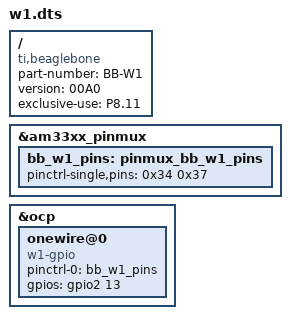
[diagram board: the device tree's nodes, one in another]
/*
* Copyright (C) 2012 Texas Instruments Incorporated - http://www.ti.com/
*
* This program is free software; you can redistribute it and/or modify
* it under the terms of the GNU General Public License version 2 as
* published by the Free Software Foundation.
* 
* Modified  by Russell Senior from the weather cape's DTS file.
* Minor formatting by C W Rose.
* 
* 
* Configuring One-wire protocol for Beaglebone Black, following instructions at
* http://www.bonebrews.com/temperature-monitoring-with-the-ds18b20-on-a-beaglebone-black/
*
* This code configures pin P8.11; if using a different pin, change the following:
* - exclusive-use
* - first entry in pinctrl-single,pins
*/



/dts-v1/;
/plugin/;

/ {
    compatible = "ti,beaglebone", "ti,beaglebone-black";
    part-number = "BB-W1";
    version = "00A0";

    exclusive-use = "P8.11";

    fragment@0 {
        target = <&am33xx_pinmux>;
        __overlay__ {
             bb_w1_pins: pinmux_bb_w1_pins {
                 pinctrl-single,pins =  <0x34 0x37 /* gpmc_ad13.gpio1_13, OMAP_PIN_INPUT_PULLUP | OMAP_MUX_MODE7 - w1-gpio */ >;
             };
        };
    };

    fragment@1 {
        target = <&ocp>;
        __overlay__ {
            onewire@0 {
                status          = "okay";
                compatible      = "w1-gpio";
                pinctrl-names   = "default";
                pinctrl-0       = <&bb_w1_pins>;

                gpios = <&gpio2 13 0>;
            };
        };
    };
};

